# CY8C5467AXI_LP108 register map
File version: 0.1
CY8C54LP
Registers are 8-bit, read-write, no defined reset value unless marked. A register's access mark holds for its fields unless they carry their own. Offsets are from the block's base; lines under a group give offsets from that group; [hi:lo] are bit positions; {n}, {i} and the like mark numbered series; 'fields as' and 'values as' point back to an identical list; <NAME> marks a mode.

## Memory map
0x00000000 OE
0x00000000 ADC_SAR — SAR ADC
0x00000000 SPIS

## OE
Base 0x00000000
0x40006575 OE_CONTROL_REG

## ADC_SAR — SAR ADC
Base 0x00000000
0x40004614 SAR_TR0 — SAR trim register
{0x40005900+i} SAR_CSR{i} (i=0..6) — SAR status and control register {i}
0x40005B20 SAR_SW0 — SAR Analog Routing Register 0
{0x40005B20+i} SAR_SW{i} (i=2..4) — SAR Analog Routing Register {i}
0x40005B26 SAR_SW6 — SAR Analog Routing Register 6
0x40005B27 SAR_CLK — SAR Clock Selection Register
0x40005BA0 SAR_WRK 16-bit — SAR working register

## SPIS
Base 0x00000000
0x40006404 SPIS_TX_DATA
0x40006404 SPIS_RX_DATA
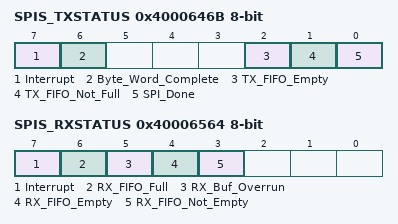
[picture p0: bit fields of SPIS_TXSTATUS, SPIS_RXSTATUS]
0x4000646B SPIS_TXSTATUS
  [7] Interrupt ro — Set when interrupt occurs
  [6] Byte_Word_Complete ro — Set when a byte/word transmit has completed
  [2] TX_FIFO_Empty ro — Set when the TX Data FIFO is empty
  [1] TX_FIFO_Not_Full ro — Set when the TX Data FIFO is not full
  [0] SPI_Done ro — Set when all of the data in the transmit FIFO has been sent. Set when Byte/Word Complete has been set and TX Data FIFO is empty
0x40006564 SPIS_RXSTATUS
  [7] Interrupt ro — Set when interrupt occurs
  [6] RX_FIFO_Full ro — Set when the RX Data FIFO is full
  [5] RX_Buf_Overrun ro — Set when RX Data has overrun the 4 byte/word FIFO without being moved to the RX buffer cmemory array (if one exists)
  [4] RX_FIFO_Empty ro — Set when the RX Data FIFO is empty
  [3] RX_FIFO_Not_Empty ro — Set when the RX Data FIFO is not empty. That is, at least one byte/word is in the RX FIFO
